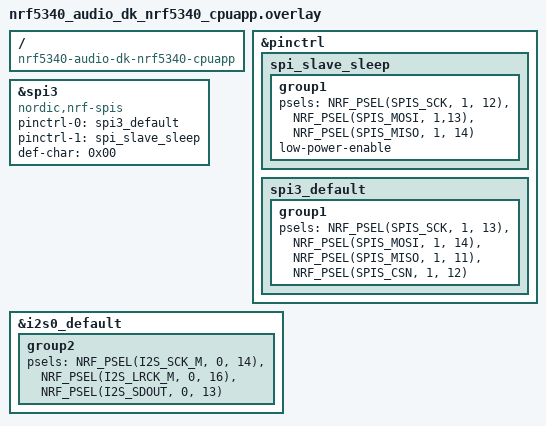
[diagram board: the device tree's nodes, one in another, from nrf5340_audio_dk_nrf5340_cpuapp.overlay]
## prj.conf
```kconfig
CONFIG_GPIO=y

# NFC pins disable
CONFIG_NFCT_PINS_AS_GPIOS=y

# Config SPI
CONFIG_SPI=y
CONFIG_SPI_SLAVE=y
```

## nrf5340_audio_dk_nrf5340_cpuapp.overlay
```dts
/*
    This c program is meant to talk with another DK
    using SPI.
    It uses the Zephyr BitBang program as its base. 

    Joao Victor Colombari Carlet
    Metamaterials Group: Microwaves and Optics
    University of Sao Paulo
    Jan, 9th, 2024
*/

&pinctrl {

	spi_slave_sleep: spi_slave_sleep {
		group1 {
			psels = <NRF_PSEL(SPIS_SCK, 1, 12)>,
					<NRF_PSEL(SPIS_MOSI, 1,13)>,
					<NRF_PSEL(SPIS_MISO, 1, 14)>;
			low-power-enable;
		};
	};

	spi3_default: spi3_default {
		group1 {
			psels = <NRF_PSEL(SPIS_SCK, 1, 13)>,
					<NRF_PSEL(SPIS_MOSI, 1, 14)>,
					<NRF_PSEL(SPIS_MISO, 1, 11)>,
					<NRF_PSEL(SPIS_CSN, 1, 12)>;
		};
	};
};

my_spi_slave: &spi3 {
	compatible = "nordic,nrf-spis";
	status = "okay";
	pinctrl-0 = <&spi3_default>;
	pinctrl-1 = <&spi_slave_sleep>;
	pinctrl-names = "default", "sleep";
	def-char = <0x00>;
};

&spi3 {
	cs-gpios = <&gpio1 15 0>;
	pinctrl-0 = <&spi3_default>;
	pinctrl-names = "default", "sleep";
};
&i2s0_default {
	group2 {
		psels = <NRF_PSEL(I2S_SCK_M, 0, 14)>,
				<NRF_PSEL(I2S_LRCK_M, 0, 16)>,
				<NRF_PSEL(I2S_SDOUT, 0, 13)>;
	};
};

&spi3 {
	/delete-property/ cs-gpios;
	pinctrl-0 = <&spi3_default>;
	pinctrl-names = "default", "sleep";
};

/ {
	compatible = "nrf5340-audio-dk-nrf5340-cpuapp";
};
```

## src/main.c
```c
#include <zephyr/kernel.h>
#include <zephyr/device.h>
#include <zephyr/devicetree.h>
#include <zephyr/drivers/gpio.h>
#include <zephyr/drivers/spi.h>

#define MY_SPI_SLAVE  DT_NODELABEL(my_spi_slave)

void spi_slave(const struct device *dev)
{
	struct spi_config config;

	config.frequency = 8000000;
	config.operation = SPI_WORD_SET(8) | SPI_TRANSFER_MSB |
				 SPI_MODE_CPOL | SPI_MODE_CPHA | SPI_OP_MODE_SLAVE,
	config.slave = 0;	

	enum { datacount = 5 };
	uint8_t buff[datacount] = { 0x05, 0x04, 0x03, 0x02, 0x01};
	uint8_t rxdata[datacount];

	struct spi_buf tx_buf[1] = { {.buf = buff, .len = sizeof(buff)}};
	struct spi_buf rx_buf[1] = { {.buf = rxdata, .len = sizeof(rxdata)}};

	struct spi_buf_set tx_set = { .buffers = tx_buf, .count = 1 };
	struct spi_buf_set rx_set = { .buffers = rx_buf, .count = 1 };

	int ret = spi_transceive(dev, &config, &tx_set, &rx_set);

	printf("Slave ret: %d\n", ret);
	printf(" tx (i)  : %02x %02x %02x %02x %02x\n",
	       buff[0], buff[1], buff[2], buff[3], buff[4]);
	printf(" rx (i)  : %02x %02x %02x %02x %02x\n",
	       rxdata[0], rxdata[1], rxdata[2], rxdata[3], rxdata[4]);
}

int main(void)
{
	const struct device *dev = DEVICE_DT_GET(MY_SPI_SLAVE);

	if (!device_is_ready(dev)) {
		printk("%s: device not ready.\n", dev->name);
		return 0;
	}

	while (1) {
		spi_slave(dev);
		k_sleep(K_MSEC(2000));
	}
	return 0;
}
```
